# max32630 register map
Vendor: Maxim Integrated; Series: max3263x; File version: 1.2
CPU: CM4 r0p1, little endian, no MPU, FPU, 3 interrupt priority bits
Registers are 32-bit, read-write, reset 0x0 unless marked. A register's access mark holds for its fields unless they carry their own. Offsets are from the block's base; [hi:lo] are bit positions; {n}, {i} and the like mark numbered series; 'fields as' and 'values as' point back to an identical list.

## TPU_TSR — Trust Protection Unit (TPU)
Base 0x40007C00
{0x10+4i} SKS{i} (i=0..3) — TPU Secure Key Storage Register {i} (Cleared on Tamper Detect)

## AES — AES Cryptographic Engine
Base 0x40007400
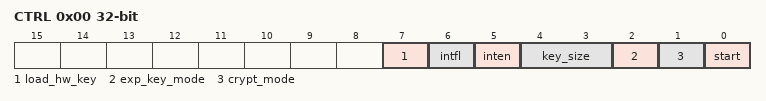
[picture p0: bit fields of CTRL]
0x00 CTRL — AES Control and Status
  [7] load_hw_key — Load Hardware Key
  [6] intfl write-1-clears — AES Interrupt Flag
  [5] inten — AES Interrupt Enable
  [4:3] key_size — AES Key Size Select
    0=Use 128-bit AES key size; 1=Use 192-bit AES key size; 2=Use 256-bit AES key size
  [2] exp_key_mode — AES Expanded Key Mode
    0=CALC_NEW_EXP_KEY (Calculate new expanded key for this operation.); 1=USE_LAST_EXP_KEY (Use expanded key calculated by the last operation.)
  [1] crypt_mode — AES Encrypt/Decrypt Mode
    0=ENCRYPT_MODE (Perform AES encryption operation.); 1=DECRYPT_MODE (Perform AES decryption operation.)
  [0] start — AES Start/Busy
0x08 ERASE_ALL — Write to Trigger AES Memory Erase

## MAA — MAA Cryptographic Engine
Base 0x40007800
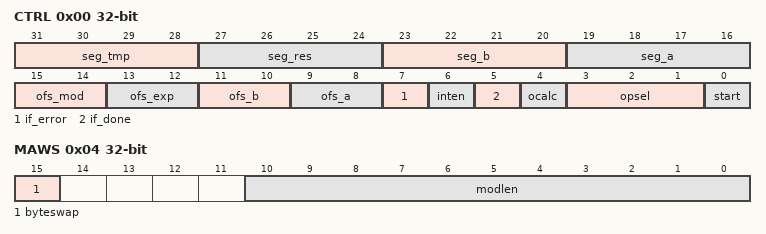
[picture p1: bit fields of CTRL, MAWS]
0x00 CTRL — MAA Control, Configuration and Status
  [31:28] seg_tmp — Temporary Memory Segment Select
  [27:24] seg_res — Result Memory Segment Select
  [23:20] seg_b — Operand B Memory Segment Select
  [19:16] seg_a — Operand A Memory Segment Select
  [15:14] ofs_mod — Modulus Memory Select
  [13:12] ofs_exp — Exponent Memory Offset Select
  [11:10] ofs_b — Operand B Memory Offset Select
  [9:8] ofs_a — Operand A Memory Offset Select
  [7] if_error — Interrupt Flag - Error
  [6] inten — MAA Interrupt Enable
  [5] if_done — Interrupt Flag - Calculation Done
  [4] ocalc — Optimized Calculation Control
  [3:1] opsel — Select Operation Type
    0=EXP (Exponentiation.); 1=SQR (Square operation.); 2=MUL (Multiply.); 3=SQRMUL (Square operation followed by multiply.); 4=ADD (Addition.); 5=SUB (Subtraction.)
  [0] start — Start MAA Calculation
0x04 MAWS — MAA Word (Operand) Size, Big/Little Endian Mode Select
  [15] byteswap — Big Endian Byte Mode
  [10:0] modlen — MAA Word Size

## WDT0 — Watchdog Timers
Base 0x40008000
Same registers: WDT1 0x40009000
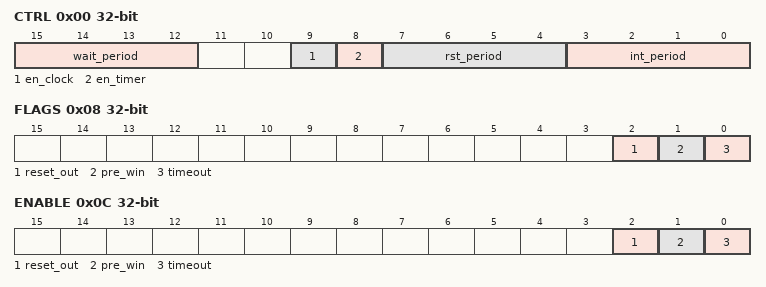
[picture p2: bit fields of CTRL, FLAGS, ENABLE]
0x00 CTRL — Watchdog Timer Control Register
  [15:12] wait_period — Period from WDT Clear to Clear Window Begin
    0=2_31_CLKS (2^31 WDT clocks.); 1=2_30_CLKS (2^30 WDT clocks.); 2=2_29_CLKS (2^29 WDT clocks.); 3=2_28_CLKS (2^28 WDT clocks.); 4=2_27_CLKS (2^27 WDT clocks.); 5=2_26_CLKS (2^26 WDT clocks.); 6=2_25_CLKS (2^25 WDT clocks.); 7=2_24_CLKS (2^24 WDT clocks.); 8=2_23_CLKS (2^23 WDT clocks.); 9=2_22_CLKS (2^22 WDT clocks.); 10=2_21_CLKS (2^21 WDT clocks.); 11=2_20_CLKS (2^20 WDT clocks.); 12=2_19_CLKS (2^19 WDT clocks.); 13=2_18_CLKS (2^18 WDT clocks.); 14=2_17_CLKS (2^17 WDT clocks.); 15=2_16_CLKS (2^16 WDT clocks.)
  [9] en_clock — Watchdog Clock Gate
  [8] en_timer — Watchdog Timer Enable
  [7:4] rst_period — Period from WDT Clear to Reset Flag Set
    values as wait_period
  [3:0] int_period — Period from WDT Clear to Interrupt Flag Set
    values as wait_period
0x04 CLEAR — Watchdog Timer Clear Register (Feed Dog)
0x08 FLAGS — Watchdog Timer Interrupt and Reset Flags
  [2] reset_out write-1-clears — Watchdog Reset Flag
  [1] pre_win write-1-clears — Watchdog Pre-Window Clear Interrupt Flag
  [0] timeout write-1-clears — Watchdog Timeout Interrupt Flag
0x0C ENABLE — Watchdog Timer Interrupt/Reset Enable/Disable Controls
  [2] reset_out — Enable Watchdog Reset Output
  [1] pre_win — Enable Watchdog Pre-Window Reset Interrupt
  [0] timeout — Enable Watchdog Interrupt
0x14 LOCK_CTRL — Watchdog Timer Register Setting Lock for Control Register
  [7:0] wdlock — Lock for Control Register

## WDT2 — Low-Level Watchdog Timer
Base 0x40007C60
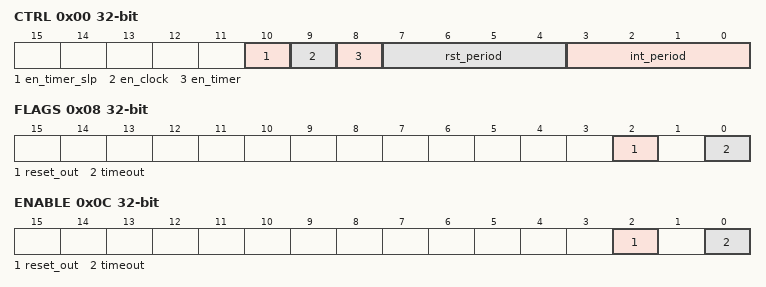
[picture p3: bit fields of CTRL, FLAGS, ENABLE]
0x00 CTRL — Watchdog Timer 2 Control Register
  [10] en_timer_slp — Watchdog Timer Enable in Sleep Mode
  [9] en_clock — Watchdog Clock Gate
  [8] en_timer — Watchdog Timer Enable in Run Mode
  [7:4] rst_period — Period from WDT Clear to Reset Flag Set
    0=2_25_NANO_CLKS (2^25 nanoring clocks.); 1=2_24_NANO_CLKS (2^24 nanoring clocks.); 2=2_23_NANO_CLKS (2^23 nanoring clocks.); 3=2_22_NANO_CLKS (2^22 nanoring clocks.); 4=2_21_NANO_CLKS (2^21 nanoring clocks.); 5=2_20_NANO_CLKS (2^20 nanoring clocks.); 6=2_19_NANO_CLKS (2^19 nanoring clocks.); 7=2_18_NANO_CLKS (2^18 nanoring clocks.); 8=2_17_NANO_CLKS (2^17 nanoring clocks.); 9=2_16_NANO_CLKS (2^16 nanoring clocks.); 10=2_15_NANO_CLKS (2^15 nanoring clocks.); 11=2_14_NANO_CLKS (2^14 nanoring clocks.); 12=2_13_NANO_CLKS (2^13 nanoring clocks.); 13=2_12_NANO_CLKS (2^12 nanoring clocks.); 14=2_11_NANO_CLKS (2^11 nanoring clocks.); 15=2_10_NANO_CLKS (2^10 nanoring clocks.)
  [3:0] int_period — Period from WDT Clear to Interrupt Flag Set
    values as rst_period
0x04 CLEAR — Watchdog Timer 2 Clear Register (Feed Dog)
0x08 FLAGS — Watchdog Timer 2 Interrupt and Reset Flags
  [2] reset_out write-1-clears — Watchdog Reset Flag
  [0] timeout write-1-clears — Watchdog Timeout Interrupt Flag
0x0C ENABLE — Watchdog Timer 2 Interrupt/Reset Enable/Disable Controls
  [2] reset_out — Enable Watchdog Reset Output
  [0] timeout — Enable Watchdog Timeout Interrupt
0x14 LOCK_CTRL — Watchdog Timer 2 Register Setting Lock for Control Registers
  [7:0] wdlock — Lock for Control and Enable Register
